# nrf7120E_enga_application register map
Vendor: Nordic Semiconductor; Series: nrf71; File version: 1
CPU: CM33 r0p4, little endian, MPU, FPU, 3 interrupt priority bits, 270 interrupts, 4 SAU regions
Registers are 32-bit, read-write, reset 0x0 unless marked. A register's access mark holds for its fields unless they carry their own. Offsets are from the block's base; [hi:lo] are bit positions; lines under a group give offsets from that group; {n}, {i} and the like mark numbered series; 'fields as' and 'values as' point back to an identical list.

## GLOBAL_AUXPLL_NS — AUXPLL 0
Base 0x40130000
Same registers: GLOBAL_AUXPLL_S 0x50130000
0x00 TASKS_START wo — Start the AUXPLL
  [0] TASKS_START
    1=Trigger task
0x04 TASKS_STOP wo — Stop the AUXPLL
  [0] TASKS_STOP
    1=Trigger task
0x08 TASKS_NEWFINEFREQ wo — Change fine frequency
  [0] TASKS_NEWFINEFREQ
    1=Trigger task
0x0C TASKS_NEWBASEFREQ wo — Change base frequency
  [0] TASKS_NEWBASEFREQ
    1=Trigger task
0x10 TASKS_FREQINCSTART wo — Start automated frequency increment
  [0] TASKS_FREQINCSTART
    1=Trigger task
0x14 TASKS_FREQINCSTOP wo — Stop automated frequency increment
  [0] TASKS_FREQINCSTOP
    1=Trigger task
0x100 EVENTS_STARTED — AUXPLL started
  [0] EVENTS_STARTED
    0=NotGenerated (Event not generated); 1=Generated (Event generated)
0x104 EVENTS_STOPPED — AUXPLL stopped
  [0] EVENTS_STOPPED
    values as EVENTS_STARTED.EVENTS_STARTED
0x108 EVENTS_LOCKED — AUXPLL locked
  [0] EVENTS_LOCKED
    values as EVENTS_STARTED.EVENTS_STARTED
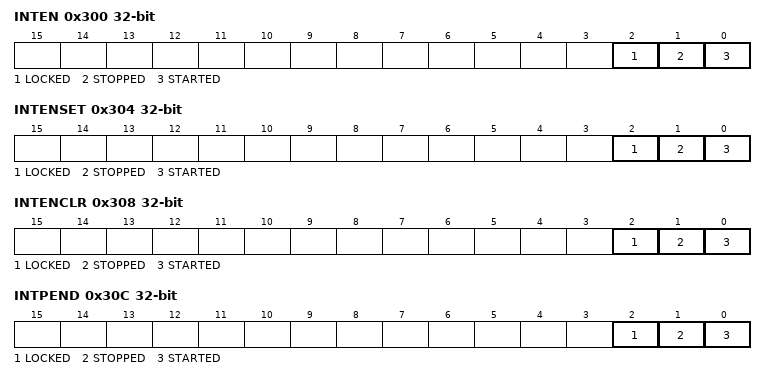
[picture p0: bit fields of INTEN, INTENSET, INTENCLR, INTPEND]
0x300 INTEN — Enable or disable interrupt
  [all] fields
    0=Disabled; 1=Enabled
  [2] LOCKED — Enable or disable interrupt for event LOCKED
  [1] STOPPED — Enable or disable interrupt for event STOPPED
  [0] STARTED — Enable or disable interrupt for event STARTED
0x304 INTENSET — Enable interrupt
  [all] fields
    on read: 0=Disabled (Read: Disabled); 1=Enabled (Read: Enabled) | on write: 1=Set (Enable)
  [2] LOCKED write-1-sets — Write '1' to enable interrupt for event LOCKED
  [1] STOPPED write-1-sets — Write '1' to enable interrupt for event STOPPED
  [0] STARTED write-1-sets — Write '1' to enable interrupt for event STARTED
0x308 INTENCLR — Disable interrupt
  [all] fields
    on read: 0=Disabled (Read: Disabled); 1=Enabled (Read: Enabled) | on write: 1=Clear (Disable)
  [2] LOCKED write-1-clears — Write '1' to disable interrupt for event LOCKED
  [1] STOPPED write-1-clears — Write '1' to disable interrupt for event STOPPED
  [0] STARTED write-1-clears — Write '1' to disable interrupt for event STARTED
0x30C INTPEND ro — Pending interrupts
  [all] fields
    on read: 0=NotPending (Read: Not pending); 1=Pending (Read: Pending)
  [2] LOCKED — Read pending status of interrupt for event LOCKED
  [1] STOPPED — Read pending status of interrupt for event STOPPED
  [0] STARTED — Read pending status of interrupt for event STARTED
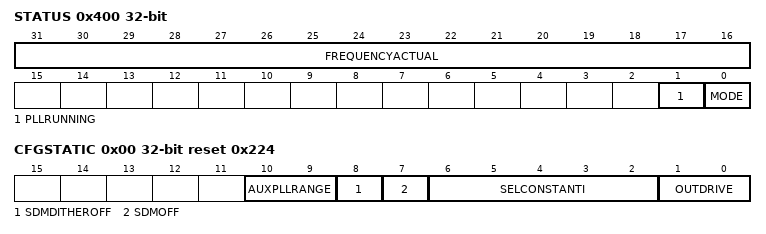
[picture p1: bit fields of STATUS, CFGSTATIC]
0x400 STATUS ro — Status of AUXPLL
  [31:16] FREQUENCYACTUAL — Actual fractional PLL divider ratio
  [1] PLLRUNNING — AUXPLL running status
    0=Off (PLL not running); 1=Running (PLL running)
  [0] MODE — AUXPLL mode
    0=Freerunning mode; 1=Locked mode
0x410 CONFIG group — Unspecified
  0x00 CFGSTATIC reset 0x224 — AUXPLL configuration
    [10:9] AUXPLLRANGE — Loop divider base settings
      0=Low (Low range divider setting); 1=Mid (Mid range divider setting); 2=High range divider setting; 3=StaticHigh (Maximum static divider setting)
    [8] SDMDITHEROFF — Turn off dither in sigma delta modulator
      0=DitherOn (Dither enabled); 1=DitherOff (Dither disabled)
    [7] SDMOFF — Turn off sigma delta modulation
      0=SDMOn (Sigma Delta Modulator enabled); 1=SDMOff (Sigma Delta Modulator disabled)
    [6:2] SELCONSTANTI — Constant current tune for ring oscillator
      0=Min (Minimum current); 9=Default current for audio and USB; 15=Max (Maximum current)
    [1:0] OUTDRIVE — Output buffer drive strength selection
      0=Min (Lowest drive strength); 3=Max (Highest drive strength)
0x440 TRIM group — Unspecified
  0x00 CTUNE reset 0xD — Ring oscillator core process corner tuning
    [4:0] VAL — Tuning value
      0=Max (Highest frequency); 13=Default center frequency for audio and USB; 31=Min (Lowest frequency)
0x460 AUXPLLCTRL group — Unspecified
  0x00 FREQUENCY reset 0x8000 — AUXPLL frequency selection
    [15:0] FREQUENCY — Set fractional PLL divider ratio
      0=MinimumDiv (Division ratio of 4); 0x3BCD=Audio44k1 (Division ratio for audio 44.1kHz frequency family); 0x8000=USB24M (Division ratio for USB PHY 24MHz clock); 0x9BA5=Audio48k (Division ratio for audio 48kHz frequency family); 0xFFFF=MaximumDiv (Division ratio of 5)
  0x04 FREQINC — Frequency increment
    [7:0] FREQINC — Signed 8-bit frequency increment, applied to FREQUENCY
  0x08 FREQINCPERIOD — Frequency increment period in 1 us steps
    [15:0] FREQINCPERIOD — Frequency increment period
  0x0C OUTSEL reset 0x7 — AUXPLL output prescaler
    [3:0] OUTSEL — Prescaler ratio
      0=DivDisabled (Divider disabled. Bypassed external clock still supported); {v}=Div{v} (Divide by {v}) (v=1..4); 5=Div6 (Divide by 6); 6=Div8 (Divide by 8); 7=Div12 (Divide by 12); 8=Div16 (Divide by 16)
  0x10 MODE — Freerunning mode control
    [1:0] MODECTRL
      0=Automatically handled by the AUXPLL peripheral; 1=Freerun (Keep AUXPLL in freerunning mode); 2=Locked (Keep AUXPLL in locked mode)
0x480 MIRROR — Enable LOCK for mirrored registers
  [0] LOCK — Lock for mirrored registers
    0=Disabled (Lock disabled); 1=Enabled (Lock enabled)
